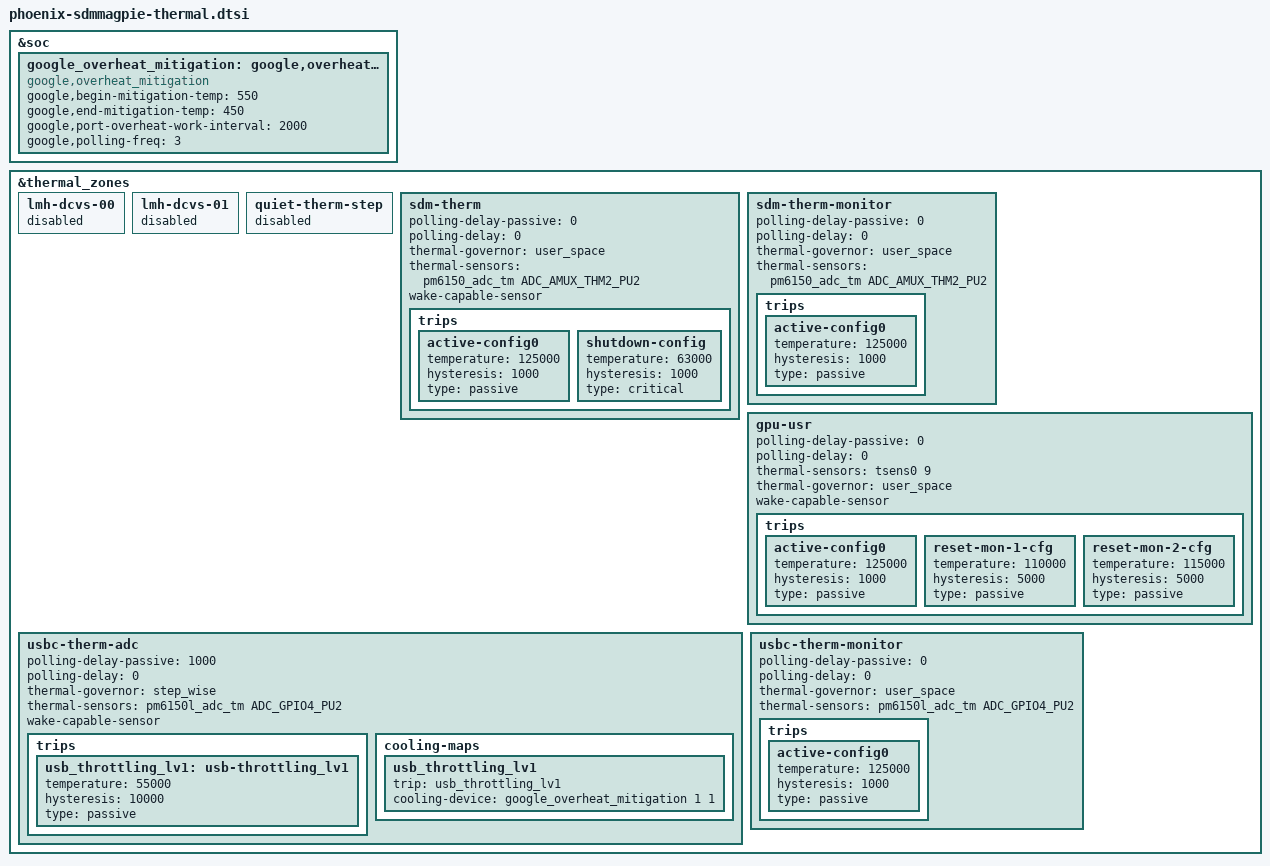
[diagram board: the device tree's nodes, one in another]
/* Copyright (c) 2020, The Linux Foundation. All rights reserved.
 *
 * This program is free software; you can redistribute it and/or modify
 * it under the terms of the GNU General Public License version 2 and
 * only version 2 as published by the Free Software Foundation.
 *
 * This program is distributed in the hope that it will be useful,
 * but WITHOUT ANY WARRANTY; without even the implied warranty of
 * MERCHANTABILITY or FITNESS FOR A PARTICULAR PURPOSE.  See the
 * GNU General Public License for more details.
 */

&soc {
	google_overheat_mitigation: google,overheat_mitigation{
		compatible = "google,overheat_mitigation";
		#cooling-cells = <2>;
		google,begin-mitigation-temp = <550>;
		google,end-mitigation-temp = <450>;
		google,port-overheat-work-interval = <2000>;
		/* Must maintain < 1/15 duty cycle */
		google,polling-freq = <3>;
	};
};

 &thermal_zones {
	lmh-dcvs-00 {
        status = "disabled";
	};

	lmh-dcvs-01 {
        status = "disabled";
	};

	quiet-therm-step {
		status = "disabled";
	};

        sdm-therm {
                polling-delay-passive = <0>;
                polling-delay = <0>;
                thermal-governor = "user_space";
                thermal-sensors = <&pm6150_adc_tm ADC_AMUX_THM2_PU2>;
                wake-capable-sensor;
                trips {
                        active-config0 {
                                temperature = <125000>;
                                hysteresis = <1000>;
                                type = "passive";
                        };
                        shutdown-config {
                                temperature = <63000>;
                                hysteresis = <1000>;
                                type = "critical";
                        };
                };
        };

	sdm-therm-monitor {
		polling-delay-passive = <0>;
		polling-delay = <0>;
		thermal-governor = "user_space";
		thermal-sensors = <&pm6150_adc_tm ADC_AMUX_THM2_PU2>;
		trips {
			active-config0 {
				temperature = <125000>;
				hysteresis = <1000>;
				type = "passive";
			};
		};
	};

        gpu-usr {
                polling-delay-passive = <0>;
                polling-delay = <0>;
                thermal-sensors = <&tsens0 9>;
                thermal-governor = "user_space";
                wake-capable-sensor;
                trips {
                        active-config0 {
                                temperature = <125000>;
                                hysteresis = <1000>;
                                type = "passive";
                        };
                        reset-mon-1-cfg {
                                temperature = <110000>;
                                hysteresis = <5000>;
                                type = "passive";
                        };
                        reset-mon-2-cfg {
                                temperature = <115000>;
                                hysteresis = <5000>;
                                type = "passive";
                        };
                };
        };

	usbc-therm-adc {
		polling-delay-passive = <1000>;
		polling-delay = <0>;
		thermal-governor = "step_wise";
		thermal-sensors = <&pm6150l_adc_tm ADC_GPIO4_PU2>;
		wake-capable-sensor;
		trips {
			usb_throttling_lv1: usb-throttling_lv1 {
				temperature = <55000>;
				hysteresis = <10000>;
				type = "passive";
			};
		};
		cooling-maps {
			usb_throttling_lv1 {
				trip = <&usb_throttling_lv1>;
				cooling-device =
					<&google_overheat_mitigation 1 1>;
			};
		};
	};

	usbc-therm-monitor {
		polling-delay-passive = <0>;
		polling-delay = <0>;
		thermal-governor = "user_space";
		thermal-sensors = <&pm6150l_adc_tm ADC_GPIO4_PU2>;
		trips {
			active-config0 {
				temperature = <125000>;
				hysteresis = <1000>;
				type = "passive";
			};
		};
	};
}; 
